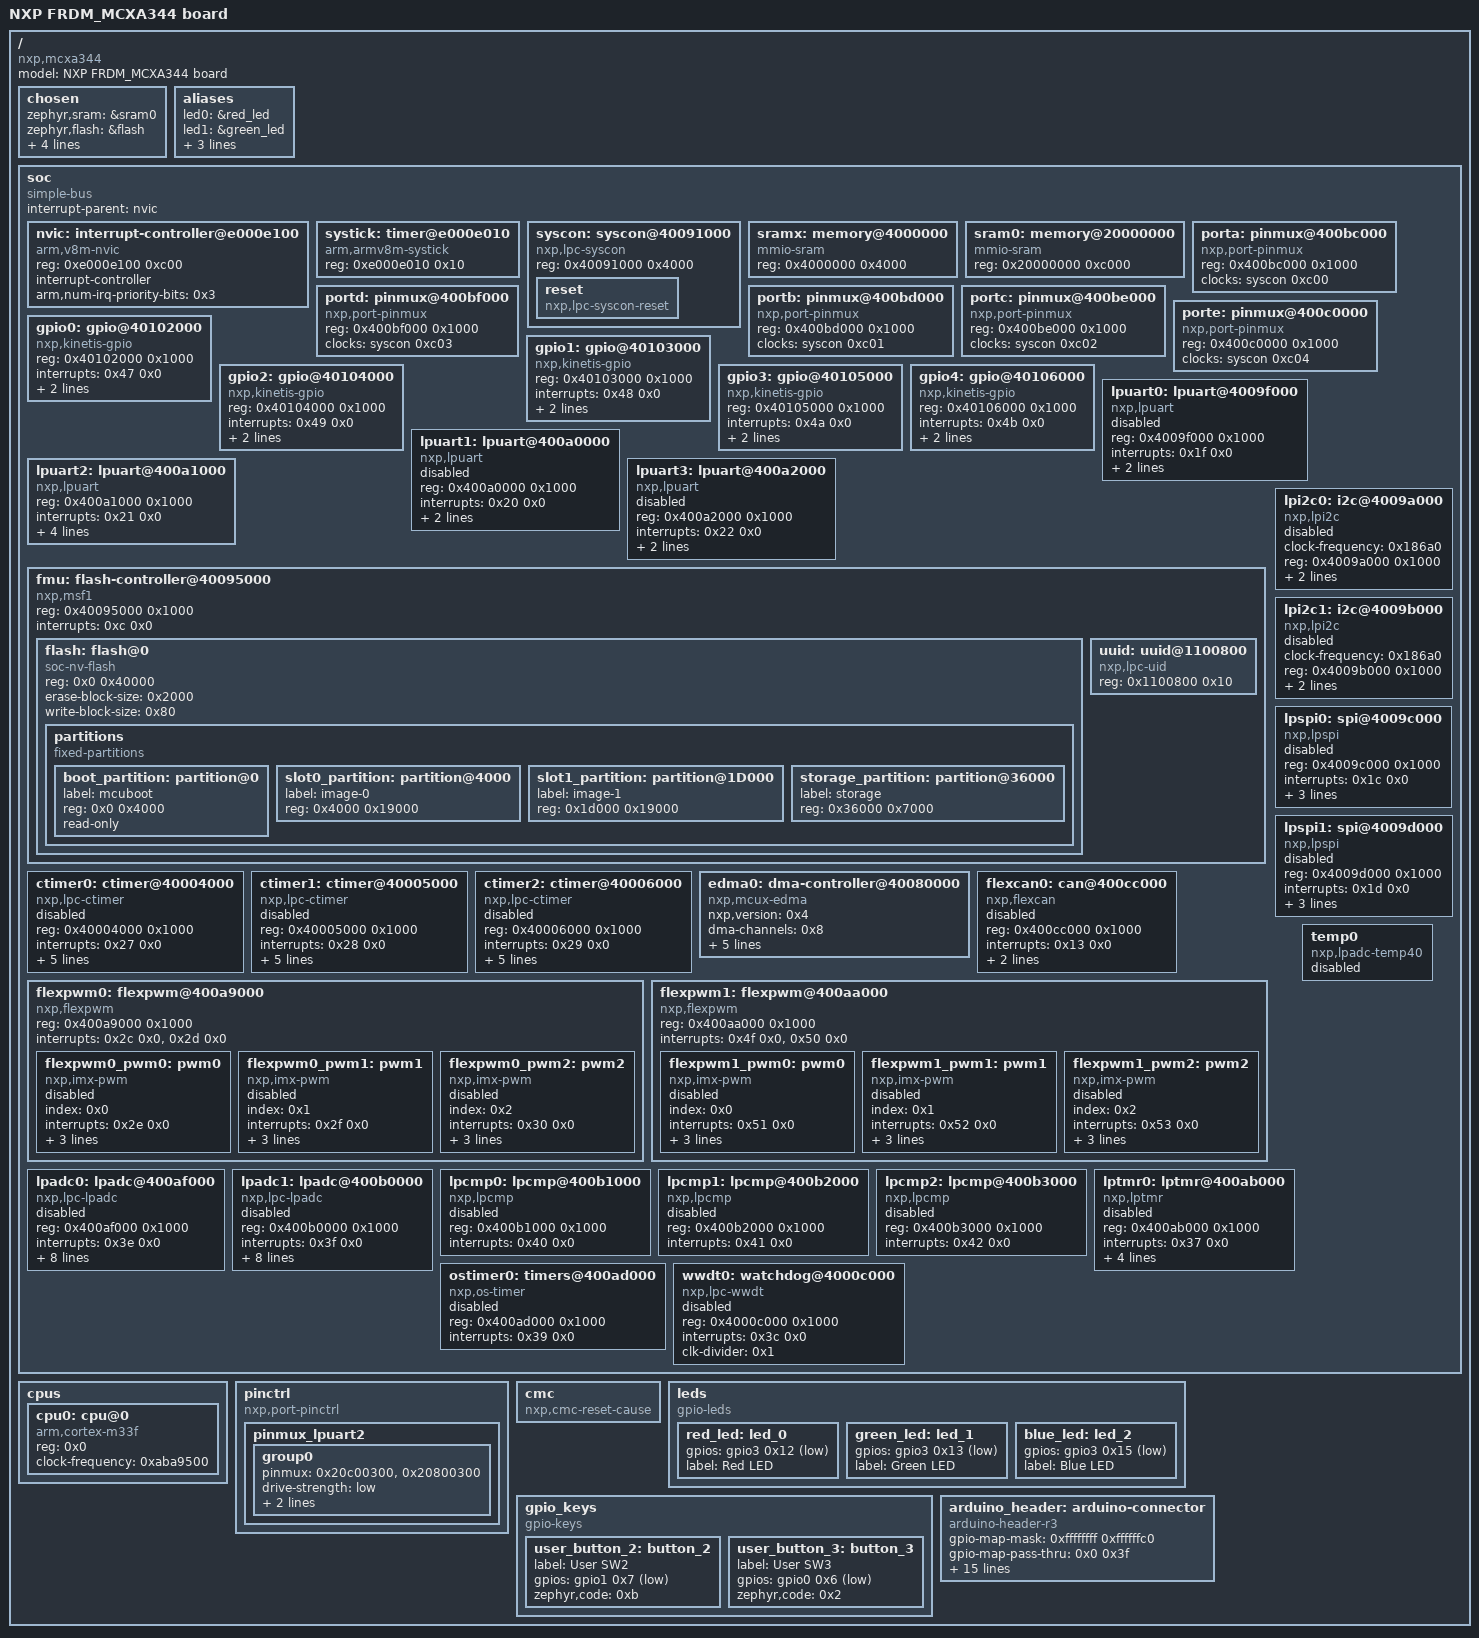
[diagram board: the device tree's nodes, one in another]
/dts-v1/;

/* node '/' defined in zephyr/dts/common/skeleton.dtsi:9 */
/ {
	#address-cells = < 0x1 >;         /* in zephyr/dts/common/skeleton.dtsi:10 */
	#size-cells = < 0x1 >;            /* in zephyr/dts/common/skeleton.dtsi:11 */
	model = "NXP FRDM_MCXA344 board"; /* in zephyr/boards/nxp/frdm_mcxa344/frdm_mcxa344.dts:15 */
	compatible = "nxp,mcxa344",
	             "nxp,mcx";           /* in zephyr/boards/nxp/frdm_mcxa344/frdm_mcxa344.dts:16 */

	/* node '/chosen' defined in zephyr/dts/common/skeleton.dtsi:13 */
	chosen {
		zephyr,sram = &sram0;                     /* in zephyr/boards/nxp/frdm_mcxa344/frdm_mcxa344.dts:27 */
		zephyr,flash = &flash;                    /* in zephyr/boards/nxp/frdm_mcxa344/frdm_mcxa344.dts:28 */
		zephyr,flash-controller = &fmu;           /* in zephyr/boards/nxp/frdm_mcxa344/frdm_mcxa344.dts:29 */
		zephyr,code-partition = &slot0_partition; /* in zephyr/boards/nxp/frdm_mcxa344/frdm_mcxa344.dts:30 */
		zephyr,console = &lpuart2;                /* in zephyr/boards/nxp/frdm_mcxa344/frdm_mcxa344.dts:31 */
		zephyr,shell-uart = &lpuart2;             /* in zephyr/boards/nxp/frdm_mcxa344/frdm_mcxa344.dts:32 */
	};

	/* node '/aliases' defined in zephyr/dts/common/skeleton.dtsi:15 */
	aliases {
		led0 = &red_led;      /* in zephyr/boards/nxp/frdm_mcxa344/frdm_mcxa344.dts:19 */
		led1 = &green_led;    /* in zephyr/boards/nxp/frdm_mcxa344/frdm_mcxa344.dts:20 */
		led2 = &blue_led;     /* in zephyr/boards/nxp/frdm_mcxa344/frdm_mcxa344.dts:21 */
		sw0 = &user_button_2; /* in zephyr/boards/nxp/frdm_mcxa344/frdm_mcxa344.dts:22 */
		sw1 = &user_button_3; /* in zephyr/boards/nxp/frdm_mcxa344/frdm_mcxa344.dts:23 */
	};

	/* node '/soc' defined in zephyr/dts/arm/armv8-m.dtsi:6 */
	soc {
		#address-cells = < 0x1 >;     /* in zephyr/dts/arm/armv8-m.dtsi:7 */
		#size-cells = < 0x1 >;        /* in zephyr/dts/arm/armv8-m.dtsi:8 */
		compatible = "simple-bus";    /* in zephyr/dts/arm/armv8-m.dtsi:9 */
		interrupt-parent = < &nvic >; /* in zephyr/dts/arm/armv8-m.dtsi:10 */
		ranges;                       /* in zephyr/dts/arm/armv8-m.dtsi:11 */

		/* node '/soc/interrupt-controller@e000e100' defined in zephyr/dts/arm/armv8-m.dtsi:13 */
		nvic: interrupt-controller@e000e100 {
			#address-cells = < 0x1 >;            /* in zephyr/dts/arm/armv8-m.dtsi:14 */
			compatible = "arm,v8m-nvic";         /* in zephyr/dts/arm/armv8-m.dtsi:15 */
			reg = < 0xe000e100 0xc00 >;          /* in zephyr/dts/arm/armv8-m.dtsi:16 */
			interrupt-controller;                /* in zephyr/dts/arm/armv8-m.dtsi:17 */
			#interrupt-cells = < 0x2 >;          /* in zephyr/dts/arm/armv8-m.dtsi:18 */
			arm,num-irq-priority-bits = < 0x3 >; /* in zephyr/dts/arm/nxp/nxp_mcxa344.dtsi:476 */
			phandle = < 0x1 >;                   /* in zephyr/dts/arm/armv8-m.dtsi:10 */
		};

		/* node '/soc/timer@e000e010' defined in zephyr/dts/arm/armv8-m.dtsi:21 */
		systick: timer@e000e010 {
			compatible = "arm,armv8m-systick"; /* in zephyr/dts/arm/armv8-m.dtsi:22 */
			reg = < 0xe000e010 0x10 >;         /* in zephyr/dts/arm/armv8-m.dtsi:23 */
		};

		/* node '/soc/syscon@40091000' defined in zephyr/dts/arm/nxp/nxp_mcxa344.dtsi:37 */
		syscon: syscon@40091000 {
			compatible = "nxp,lpc-syscon"; /* in zephyr/dts/arm/nxp/nxp_mcxa344.dtsi:38 */
			reg = < 0x40091000 0x4000 >;   /* in zephyr/dts/arm/nxp/nxp_mcxa344.dtsi:39 */
			#clock-cells = < 0x1 >;        /* in zephyr/dts/arm/nxp/nxp_mcxa344.dtsi:40 */
			phandle = < 0x2 >;             /* in zephyr/dts/arm/nxp/nxp_mcxa344.dtsi:60 */

			/* node '/soc/syscon@40091000/reset' defined in zephyr/dts/arm/nxp/nxp_mcxa344.dtsi:41 */
			reset: reset {
				compatible = "nxp,lpc-syscon-reset"; /* in zephyr/dts/arm/nxp/nxp_mcxa344.dtsi:42 */
				#reset-cells = < 0x1 >;              /* in zephyr/dts/arm/nxp/nxp_mcxa344.dtsi:43 */
			};
		};

		/* node '/soc/memory@4000000' defined in zephyr/dts/arm/nxp/nxp_mcxa344.dtsi:47 */
		sramx: memory@4000000 {
			compatible = "mmio-sram";   /* in zephyr/dts/arm/nxp/nxp_mcxa344.dtsi:48 */
			reg = < 0x4000000 0x4000 >; /* in zephyr/dts/arm/nxp/nxp_mcxa344.dtsi:49 */
		};

		/* node '/soc/memory@20000000' defined in zephyr/dts/arm/nxp/nxp_mcxa344.dtsi:52 */
		sram0: memory@20000000 {
			compatible = "mmio-sram";    /* in zephyr/dts/arm/nxp/nxp_mcxa344.dtsi:53 */
			reg = < 0x20000000 0xc000 >; /* in zephyr/dts/arm/nxp/nxp_mcxa344.dtsi:54 */
		};

		/* node '/soc/pinmux@400bc000' defined in zephyr/dts/arm/nxp/nxp_mcxa344.dtsi:57 */
		porta: pinmux@400bc000 {
			compatible = "nxp,port-pinmux"; /* in zephyr/dts/arm/nxp/nxp_mcxa344.dtsi:58 */
			reg = < 0x400bc000 0x1000 >;    /* in zephyr/dts/arm/nxp/nxp_mcxa344.dtsi:59 */
			clocks = < &syscon 0xc00 >;     /* in zephyr/dts/arm/nxp/nxp_mcxa344.dtsi:60 */
			phandle = < 0x3 >;              /* in zephyr/dts/arm/nxp/nxp_mcxa344.dtsi:94 */
		};

		/* node '/soc/pinmux@400bd000' defined in zephyr/dts/arm/nxp/nxp_mcxa344.dtsi:63 */
		portb: pinmux@400bd000 {
			compatible = "nxp,port-pinmux"; /* in zephyr/dts/arm/nxp/nxp_mcxa344.dtsi:64 */
			reg = < 0x400bd000 0x1000 >;    /* in zephyr/dts/arm/nxp/nxp_mcxa344.dtsi:65 */
			clocks = < &syscon 0xc01 >;     /* in zephyr/dts/arm/nxp/nxp_mcxa344.dtsi:66 */
			phandle = < 0x4 >;              /* in zephyr/dts/arm/nxp/nxp_mcxa344.dtsi:104 */
		};

		/* node '/soc/pinmux@400be000' defined in zephyr/dts/arm/nxp/nxp_mcxa344.dtsi:69 */
		portc: pinmux@400be000 {
			compatible = "nxp,port-pinmux"; /* in zephyr/dts/arm/nxp/nxp_mcxa344.dtsi:70 */
			reg = < 0x400be000 0x1000 >;    /* in zephyr/dts/arm/nxp/nxp_mcxa344.dtsi:71 */
			clocks = < &syscon 0xc02 >;     /* in zephyr/dts/arm/nxp/nxp_mcxa344.dtsi:72 */
			phandle = < 0x5 >;              /* in zephyr/dts/arm/nxp/nxp_mcxa344.dtsi:114 */
		};

		/* node '/soc/pinmux@400bf000' defined in zephyr/dts/arm/nxp/nxp_mcxa344.dtsi:75 */
		portd: pinmux@400bf000 {
			compatible = "nxp,port-pinmux"; /* in zephyr/dts/arm/nxp/nxp_mcxa344.dtsi:76 */
			reg = < 0x400bf000 0x1000 >;    /* in zephyr/dts/arm/nxp/nxp_mcxa344.dtsi:77 */
			clocks = < &syscon 0xc03 >;     /* in zephyr/dts/arm/nxp/nxp_mcxa344.dtsi:78 */
			phandle = < 0x6 >;              /* in zephyr/dts/arm/nxp/nxp_mcxa344.dtsi:124 */
		};

		/* node '/soc/pinmux@400c0000' defined in zephyr/dts/arm/nxp/nxp_mcxa344.dtsi:81 */
		porte: pinmux@400c0000 {
			compatible = "nxp,port-pinmux"; /* in zephyr/dts/arm/nxp/nxp_mcxa344.dtsi:82 */
			reg = < 0x400c0000 0x1000 >;    /* in zephyr/dts/arm/nxp/nxp_mcxa344.dtsi:83 */
			clocks = < &syscon 0xc04 >;     /* in zephyr/dts/arm/nxp/nxp_mcxa344.dtsi:84 */
			phandle = < 0x7 >;              /* in zephyr/dts/arm/nxp/nxp_mcxa344.dtsi:134 */
		};

		/* node '/soc/gpio@40102000' defined in zephyr/dts/arm/nxp/nxp_mcxa344.dtsi:87 */
		gpio0: gpio@40102000 {
			compatible = "nxp,kinetis-gpio"; /* in zephyr/dts/arm/nxp/nxp_mcxa344.dtsi:88 */
			reg = < 0x40102000 0x1000 >;     /* in zephyr/dts/arm/nxp/nxp_mcxa344.dtsi:90 */
			interrupts = < 0x47 0x0 >;       /* in zephyr/dts/arm/nxp/nxp_mcxa344.dtsi:91 */
			gpio-controller;                 /* in zephyr/dts/arm/nxp/nxp_mcxa344.dtsi:92 */
			#gpio-cells = < 0x2 >;           /* in zephyr/dts/arm/nxp/nxp_mcxa344.dtsi:93 */
			nxp,kinetis-port = < &porta >;   /* in zephyr/dts/arm/nxp/nxp_mcxa344.dtsi:94 */
			status = "okay";                 /* in zephyr/boards/nxp/frdm_mcxa344/frdm_mcxa344.dts:109 */
			phandle = < 0xc >;               /* in zephyr/boards/nxp/frdm_mcxa344/frdm_mcxa344.dts:65 */
		};

		/* node '/soc/gpio@40103000' defined in zephyr/dts/arm/nxp/nxp_mcxa344.dtsi:97 */
		gpio1: gpio@40103000 {
			compatible = "nxp,kinetis-gpio"; /* in zephyr/dts/arm/nxp/nxp_mcxa344.dtsi:98 */
			reg = < 0x40103000 0x1000 >;     /* in zephyr/dts/arm/nxp/nxp_mcxa344.dtsi:100 */
			interrupts = < 0x48 0x0 >;       /* in zephyr/dts/arm/nxp/nxp_mcxa344.dtsi:101 */
			gpio-controller;                 /* in zephyr/dts/arm/nxp/nxp_mcxa344.dtsi:102 */
			#gpio-cells = < 0x2 >;           /* in zephyr/dts/arm/nxp/nxp_mcxa344.dtsi:103 */
			nxp,kinetis-port = < &portb >;   /* in zephyr/dts/arm/nxp/nxp_mcxa344.dtsi:104 */
			status = "okay";                 /* in zephyr/boards/nxp/frdm_mcxa344/frdm_mcxa344.dts:113 */
			phandle = < 0xb >;               /* in zephyr/boards/nxp/frdm_mcxa344/frdm_mcxa344.dts:59 */
		};

		/* node '/soc/gpio@40104000' defined in zephyr/dts/arm/nxp/nxp_mcxa344.dtsi:107 */
		gpio2: gpio@40104000 {
			compatible = "nxp,kinetis-gpio"; /* in zephyr/dts/arm/nxp/nxp_mcxa344.dtsi:108 */
			reg = < 0x40104000 0x1000 >;     /* in zephyr/dts/arm/nxp/nxp_mcxa344.dtsi:110 */
			interrupts = < 0x49 0x0 >;       /* in zephyr/dts/arm/nxp/nxp_mcxa344.dtsi:111 */
			gpio-controller;                 /* in zephyr/dts/arm/nxp/nxp_mcxa344.dtsi:112 */
			#gpio-cells = < 0x2 >;           /* in zephyr/dts/arm/nxp/nxp_mcxa344.dtsi:113 */
			nxp,kinetis-port = < &portc >;   /* in zephyr/dts/arm/nxp/nxp_mcxa344.dtsi:114 */
			status = "okay";                 /* in zephyr/boards/nxp/frdm_mcxa344/frdm_mcxa344.dts:117 */
			phandle = < 0xd >;               /* in zephyr/boards/nxp/frdm_mcxa344/frdm_mcxa344.dts:75 */
		};

		/* node '/soc/gpio@40105000' defined in zephyr/dts/arm/nxp/nxp_mcxa344.dtsi:117 */
		gpio3: gpio@40105000 {
			compatible = "nxp,kinetis-gpio"; /* in zephyr/dts/arm/nxp/nxp_mcxa344.dtsi:118 */
			reg = < 0x40105000 0x1000 >;     /* in zephyr/dts/arm/nxp/nxp_mcxa344.dtsi:120 */
			interrupts = < 0x4a 0x0 >;       /* in zephyr/dts/arm/nxp/nxp_mcxa344.dtsi:121 */
			gpio-controller;                 /* in zephyr/dts/arm/nxp/nxp_mcxa344.dtsi:122 */
			#gpio-cells = < 0x2 >;           /* in zephyr/dts/arm/nxp/nxp_mcxa344.dtsi:123 */
			nxp,kinetis-port = < &portd >;   /* in zephyr/dts/arm/nxp/nxp_mcxa344.dtsi:124 */
			status = "okay";                 /* in zephyr/boards/nxp/frdm_mcxa344/frdm_mcxa344.dts:121 */
			phandle = < 0xa >;               /* in zephyr/boards/nxp/frdm_mcxa344/frdm_mcxa344.dts:39 */
		};

		/* node '/soc/gpio@40106000' defined in zephyr/dts/arm/nxp/nxp_mcxa344.dtsi:127 */
		gpio4: gpio@40106000 {
			compatible = "nxp,kinetis-gpio"; /* in zephyr/dts/arm/nxp/nxp_mcxa344.dtsi:128 */
			reg = < 0x40106000 0x1000 >;     /* in zephyr/dts/arm/nxp/nxp_mcxa344.dtsi:130 */
			interrupts = < 0x4b 0x0 >;       /* in zephyr/dts/arm/nxp/nxp_mcxa344.dtsi:131 */
			gpio-controller;                 /* in zephyr/dts/arm/nxp/nxp_mcxa344.dtsi:132 */
			#gpio-cells = < 0x2 >;           /* in zephyr/dts/arm/nxp/nxp_mcxa344.dtsi:133 */
			nxp,kinetis-port = < &porte >;   /* in zephyr/dts/arm/nxp/nxp_mcxa344.dtsi:134 */
			status = "okay";                 /* in zephyr/boards/nxp/frdm_mcxa344/frdm_mcxa344.dts:125 */
			phandle = < 0xe >;               /* in zephyr/boards/nxp/frdm_mcxa344/frdm_mcxa344.dts:75 */
		};

		/* node '/soc/lpuart@4009f000' defined in zephyr/dts/arm/nxp/nxp_mcxa344.dtsi:137 */
		lpuart0: lpuart@4009f000 {
			compatible = "nxp,lpuart";   /* in zephyr/dts/arm/nxp/nxp_mcxa344.dtsi:138 */
			status = "disabled";         /* in zephyr/dts/arm/nxp/nxp_mcxa344.dtsi:139 */
			reg = < 0x4009f000 0x1000 >; /* in zephyr/dts/arm/nxp/nxp_mcxa344.dtsi:140 */
			interrupts = < 0x1f 0x0 >;   /* in zephyr/dts/arm/nxp/nxp_mcxa344.dtsi:141 */
			clocks = < &syscon 0x1300 >; /* in zephyr/dts/arm/nxp/nxp_mcxa344.dtsi:142 */
			dmas = < &edma0 0x0 0x15 >,
			       < &edma0 0x1 0x16 >;  /* in zephyr/dts/arm/nxp/nxp_mcxa344.dtsi:144 */
			dma-names = "rx",
			            "tx";            /* in zephyr/dts/arm/nxp/nxp_mcxa344.dtsi:145 */
		};

		/* node '/soc/lpuart@400a0000' defined in zephyr/dts/arm/nxp/nxp_mcxa344.dtsi:148 */
		lpuart1: lpuart@400a0000 {
			compatible = "nxp,lpuart";   /* in zephyr/dts/arm/nxp/nxp_mcxa344.dtsi:149 */
			status = "disabled";         /* in zephyr/dts/arm/nxp/nxp_mcxa344.dtsi:150 */
			reg = < 0x400a0000 0x1000 >; /* in zephyr/dts/arm/nxp/nxp_mcxa344.dtsi:151 */
			interrupts = < 0x20 0x0 >;   /* in zephyr/dts/arm/nxp/nxp_mcxa344.dtsi:152 */
			clocks = < &syscon 0x1301 >; /* in zephyr/dts/arm/nxp/nxp_mcxa344.dtsi:153 */
			dmas = < &edma0 0x2 0x17 >,
			       < &edma0 0x3 0x18 >;  /* in zephyr/dts/arm/nxp/nxp_mcxa344.dtsi:155 */
			dma-names = "rx",
			            "tx";            /* in zephyr/dts/arm/nxp/nxp_mcxa344.dtsi:156 */
		};

		/* node '/soc/lpuart@400a1000' defined in zephyr/dts/arm/nxp/nxp_mcxa344.dtsi:159 */
		lpuart2: lpuart@400a1000 {
			compatible = "nxp,lpuart";       /* in zephyr/dts/arm/nxp/nxp_mcxa344.dtsi:160 */
			reg = < 0x400a1000 0x1000 >;     /* in zephyr/dts/arm/nxp/nxp_mcxa344.dtsi:162 */
			interrupts = < 0x21 0x0 >;       /* in zephyr/dts/arm/nxp/nxp_mcxa344.dtsi:163 */
			clocks = < &syscon 0x1302 >;     /* in zephyr/dts/arm/nxp/nxp_mcxa344.dtsi:164 */
			dmas = < &edma0 0x4 0x19 >,
			       < &edma0 0x5 0x1a >;      /* in zephyr/dts/arm/nxp/nxp_mcxa344.dtsi:166 */
			dma-names = "rx",
			            "tx";                /* in zephyr/dts/arm/nxp/nxp_mcxa344.dtsi:167 */
			status = "okay";                 /* in zephyr/boards/nxp/frdm_mcxa344/frdm_mcxa344.dts:129 */
			current-speed = < 0x1c200 >;     /* in zephyr/boards/nxp/frdm_mcxa344/frdm_mcxa344.dts:130 */
			pinctrl-0 = < &pinmux_lpuart2 >; /* in zephyr/boards/nxp/frdm_mcxa344/frdm_mcxa344.dts:131 */
			pinctrl-names = "default";       /* in zephyr/boards/nxp/frdm_mcxa344/frdm_mcxa344.dts:132 */
		};

		/* node '/soc/lpuart@400a2000' defined in zephyr/dts/arm/nxp/nxp_mcxa344.dtsi:170 */
		lpuart3: lpuart@400a2000 {
			compatible = "nxp,lpuart";   /* in zephyr/dts/arm/nxp/nxp_mcxa344.dtsi:171 */
			status = "disabled";         /* in zephyr/dts/arm/nxp/nxp_mcxa344.dtsi:172 */
			reg = < 0x400a2000 0x1000 >; /* in zephyr/dts/arm/nxp/nxp_mcxa344.dtsi:173 */
			interrupts = < 0x22 0x0 >;   /* in zephyr/dts/arm/nxp/nxp_mcxa344.dtsi:174 */
			clocks = < &syscon 0x1303 >; /* in zephyr/dts/arm/nxp/nxp_mcxa344.dtsi:175 */
			dmas = < &edma0 0x6 0x1b >,
			       < &edma0 0x7 0x1c >;  /* in zephyr/dts/arm/nxp/nxp_mcxa344.dtsi:177 */
			dma-names = "rx",
			            "tx";            /* in zephyr/dts/arm/nxp/nxp_mcxa344.dtsi:178 */
		};

		/* node '/soc/flash-controller@40095000' defined in zephyr/dts/arm/nxp/nxp_mcxa344.dtsi:181 */
		fmu: flash-controller@40095000 {
			compatible = "nxp,msf1";     /* in zephyr/dts/arm/nxp/nxp_mcxa344.dtsi:182 */
			reg = < 0x40095000 0x1000 >; /* in zephyr/dts/arm/nxp/nxp_mcxa344.dtsi:183 */
			interrupts = < 0xc 0x0 >;    /* in zephyr/dts/arm/nxp/nxp_mcxa344.dtsi:184 */
			#address-cells = < 0x1 >;    /* in zephyr/dts/arm/nxp/nxp_mcxa344.dtsi:186 */
			#size-cells = < 0x1 >;       /* in zephyr/dts/arm/nxp/nxp_mcxa344.dtsi:187 */

			/* node '/soc/flash-controller@40095000/flash@0' defined in zephyr/dts/arm/nxp/nxp_mcxa344.dtsi:189 */
			flash: flash@0 {
				compatible = "soc-nv-flash";   /* in zephyr/dts/arm/nxp/nxp_mcxa344.dtsi:190 */
				reg = < 0x0 0x40000 >;         /* in zephyr/dts/arm/nxp/nxp_mcxa344.dtsi:191 */
				erase-block-size = < 0x2000 >; /* in zephyr/dts/arm/nxp/nxp_mcxa344.dtsi:192 */
				write-block-size = < 0x80 >;   /* in zephyr/dts/arm/nxp/nxp_mcxa344.dtsi:193 */

				/* node '/soc/flash-controller@40095000/flash@0/partitions' defined in zephyr/boards/nxp/frdm_mcxa344/frdm_mcxa344.dts:136 */
				partitions {
					compatible = "fixed-partitions"; /* in zephyr/boards/nxp/frdm_mcxa344/frdm_mcxa344.dts:137 */
					#address-cells = < 0x1 >;        /* in zephyr/boards/nxp/frdm_mcxa344/frdm_mcxa344.dts:138 */
					#size-cells = < 0x1 >;           /* in zephyr/boards/nxp/frdm_mcxa344/frdm_mcxa344.dts:139 */

					/* node '/soc/flash-controller@40095000/flash@0/partitions/partition@0' defined in zephyr/boards/nxp/frdm_mcxa344/frdm_mcxa344.dts:141 */
					boot_partition: partition@0 {
						label = "mcuboot";    /* in zephyr/boards/nxp/frdm_mcxa344/frdm_mcxa344.dts:142 */
						reg = < 0x0 0x4000 >; /* in zephyr/boards/nxp/frdm_mcxa344/frdm_mcxa344.dts:143 */
						read-only;            /* in zephyr/boards/nxp/frdm_mcxa344/frdm_mcxa344.dts:144 */
					};

					/* node '/soc/flash-controller@40095000/flash@0/partitions/partition@4000' defined in zephyr/boards/nxp/frdm_mcxa344/frdm_mcxa344.dts:147 */
					slot0_partition: partition@4000 {
						label = "image-0";        /* in zephyr/boards/nxp/frdm_mcxa344/frdm_mcxa344.dts:148 */
						reg = < 0x4000 0x19000 >; /* in zephyr/boards/nxp/frdm_mcxa344/frdm_mcxa344.dts:149 */
					};

					/* node '/soc/flash-controller@40095000/flash@0/partitions/partition@1D000' defined in zephyr/boards/nxp/frdm_mcxa344/frdm_mcxa344.dts:152 */
					slot1_partition: partition@1D000 {
						label = "image-1";         /* in zephyr/boards/nxp/frdm_mcxa344/frdm_mcxa344.dts:153 */
						reg = < 0x1d000 0x19000 >; /* in zephyr/boards/nxp/frdm_mcxa344/frdm_mcxa344.dts:154 */
					};

					/* node '/soc/flash-controller@40095000/flash@0/partitions/partition@36000' defined in zephyr/boards/nxp/frdm_mcxa344/frdm_mcxa344.dts:157 */
					storage_partition: partition@36000 {
						label = "storage";        /* in zephyr/boards/nxp/frdm_mcxa344/frdm_mcxa344.dts:158 */
						reg = < 0x36000 0x7000 >; /* in zephyr/boards/nxp/frdm_mcxa344/frdm_mcxa344.dts:159 */
					};
				};
			};

			/* node '/soc/flash-controller@40095000/uuid@1100800' defined in zephyr/dts/arm/nxp/nxp_mcxa344.dtsi:196 */
			uuid: uuid@1100800 {
				compatible = "nxp,lpc-uid"; /* in zephyr/dts/arm/nxp/nxp_mcxa344.dtsi:197 */
				reg = < 0x1100800 0x10 >;   /* in zephyr/dts/arm/nxp/nxp_mcxa344.dtsi:198 */
			};
		};

		/* node '/soc/ctimer@40004000' defined in zephyr/dts/arm/nxp/nxp_mcxa344.dtsi:202 */
		ctimer0: ctimer@40004000 {
			compatible = "nxp,lpc-ctimer"; /* in zephyr/dts/arm/nxp/nxp_mcxa344.dtsi:203 */
			reg = < 0x40004000 0x1000 >;   /* in zephyr/dts/arm/nxp/nxp_mcxa344.dtsi:204 */
			interrupts = < 0x27 0x0 >;     /* in zephyr/dts/arm/nxp/nxp_mcxa344.dtsi:205 */
			status = "disabled";           /* in zephyr/dts/arm/nxp/nxp_mcxa344.dtsi:206 */
			clk-source = < 0x1 >;          /* in zephyr/dts/arm/nxp/nxp_mcxa344.dtsi:207 */
			clocks = < &syscon 0x0 >;      /* in zephyr/dts/arm/nxp/nxp_mcxa344.dtsi:208 */
			mode = < 0x0 >;                /* in zephyr/dts/arm/nxp/nxp_mcxa344.dtsi:209 */
			input = < 0x0 >;               /* in zephyr/dts/arm/nxp/nxp_mcxa344.dtsi:210 */
			prescale = < 0x0 >;            /* in zephyr/dts/arm/nxp/nxp_mcxa344.dtsi:211 */
		};

		/* node '/soc/ctimer@40005000' defined in zephyr/dts/arm/nxp/nxp_mcxa344.dtsi:214 */
		ctimer1: ctimer@40005000 {
			compatible = "nxp,lpc-ctimer"; /* in zephyr/dts/arm/nxp/nxp_mcxa344.dtsi:215 */
			reg = < 0x40005000 0x1000 >;   /* in zephyr/dts/arm/nxp/nxp_mcxa344.dtsi:216 */
			interrupts = < 0x28 0x0 >;     /* in zephyr/dts/arm/nxp/nxp_mcxa344.dtsi:217 */
			status = "disabled";           /* in zephyr/dts/arm/nxp/nxp_mcxa344.dtsi:218 */
			clk-source = < 0x1 >;          /* in zephyr/dts/arm/nxp/nxp_mcxa344.dtsi:219 */
			clocks = < &syscon 0x1 >;      /* in zephyr/dts/arm/nxp/nxp_mcxa344.dtsi:220 */
			mode = < 0x0 >;                /* in zephyr/dts/arm/nxp/nxp_mcxa344.dtsi:221 */
			input = < 0x0 >;               /* in zephyr/dts/arm/nxp/nxp_mcxa344.dtsi:222 */
			prescale = < 0x0 >;            /* in zephyr/dts/arm/nxp/nxp_mcxa344.dtsi:223 */
		};

		/* node '/soc/ctimer@40006000' defined in zephyr/dts/arm/nxp/nxp_mcxa344.dtsi:226 */
		ctimer2: ctimer@40006000 {
			compatible = "nxp,lpc-ctimer"; /* in zephyr/dts/arm/nxp/nxp_mcxa344.dtsi:227 */
			reg = < 0x40006000 0x1000 >;   /* in zephyr/dts/arm/nxp/nxp_mcxa344.dtsi:228 */
			interrupts = < 0x29 0x0 >;     /* in zephyr/dts/arm/nxp/nxp_mcxa344.dtsi:229 */
			status = "disabled";           /* in zephyr/dts/arm/nxp/nxp_mcxa344.dtsi:230 */
			clk-source = < 0x1 >;          /* in zephyr/dts/arm/nxp/nxp_mcxa344.dtsi:231 */
			clocks = < &syscon 0x2 >;      /* in zephyr/dts/arm/nxp/nxp_mcxa344.dtsi:232 */
			mode = < 0x0 >;                /* in zephyr/dts/arm/nxp/nxp_mcxa344.dtsi:233 */
			input = < 0x0 >;               /* in zephyr/dts/arm/nxp/nxp_mcxa344.dtsi:234 */
			prescale = < 0x0 >;            /* in zephyr/dts/arm/nxp/nxp_mcxa344.dtsi:235 */
		};

		/* node '/soc/dma-controller@40080000' defined in zephyr/dts/arm/nxp/nxp_mcxa344.dtsi:238 */
		edma0: dma-controller@40080000 {
			#dma-cells = < 0x2 >;         /* in zephyr/dts/arm/nxp/nxp_mcxa344.dtsi:239 */
			compatible = "nxp,mcux-edma"; /* in zephyr/dts/arm/nxp/nxp_mcxa344.dtsi:240 */
			nxp,version = < 0x4 >;        /* in zephyr/dts/arm/nxp/nxp_mcxa344.dtsi:241 */
			dma-channels = < 0x8 >;       /* in zephyr/dts/arm/nxp/nxp_mcxa344.dtsi:242 */
			dma-requests = < 0x56 >;      /* in zephyr/dts/arm/nxp/nxp_mcxa344.dtsi:243 */
			reg = < 0x40080000 0x1000 >;  /* in zephyr/dts/arm/nxp/nxp_mcxa344.dtsi:245 */
			interrupts = < 0x2 0x0 >,
			             < 0x3 0x0 >,
			             < 0x4 0x0 >,
			             < 0x5 0x0 >,
			             < 0x6 0x0 >,
			             < 0x7 0x0 >,
			             < 0x8 0x0 >,
			             < 0x9 0x0 >;     /* in zephyr/dts/arm/nxp/nxp_mcxa344.dtsi:246 */
			no-error-irq;                 /* in zephyr/dts/arm/nxp/nxp_mcxa344.dtsi:248 */
			status = "okay";              /* in zephyr/boards/nxp/frdm_mcxa344/frdm_mcxa344.dts:105 */
			phandle = < 0x8 >;            /* in zephyr/dts/arm/nxp/nxp_mcxa344.dtsi:144 */
		};

		/* node '/soc/can@400cc000' defined in zephyr/dts/arm/nxp/nxp_mcxa344.dtsi:252 */
		flexcan0: can@400cc000 {
			compatible = "nxp,flexcan";  /* in zephyr/dts/arm/nxp/nxp_mcxa344.dtsi:253 */
			reg = < 0x400cc000 0x1000 >; /* in zephyr/dts/arm/nxp/nxp_mcxa344.dtsi:254 */
			interrupts = < 0x13 0x0 >;   /* in zephyr/dts/arm/nxp/nxp_mcxa344.dtsi:255 */
			interrupt-names = "common";  /* in zephyr/dts/arm/nxp/nxp_mcxa344.dtsi:256 */
			clocks = < &syscon 0x1000 >; /* in zephyr/dts/arm/nxp/nxp_mcxa344.dtsi:257 */
			clk-source = < 0x0 >;        /* in zephyr/dts/arm/nxp/nxp_mcxa344.dtsi:258 */
			status = "disabled";         /* in zephyr/dts/arm/nxp/nxp_mcxa344.dtsi:259 */
		};

		/* node '/soc/flexpwm@400a9000' defined in zephyr/dts/arm/nxp/nxp_mcxa344.dtsi:262 */
		flexpwm0: flexpwm@400a9000 {
			compatible = "nxp,flexpwm";       /* in zephyr/dts/arm/nxp/nxp_mcxa344.dtsi:263 */
			reg = < 0x400a9000 0x1000 >;      /* in zephyr/dts/arm/nxp/nxp_mcxa344.dtsi:264 */
			interrupt-names = "RELOAD-ERROR",
			                  "FAULT";        /* in zephyr/dts/arm/nxp/nxp_mcxa344.dtsi:265 */
			interrupts = < 0x2c 0x0 >,
			             < 0x2d 0x0 >;        /* in zephyr/dts/arm/nxp/nxp_mcxa344.dtsi:266 */

			/* node '/soc/flexpwm@400a9000/pwm0' defined in zephyr/dts/arm/nxp/nxp_mcxa344.dtsi:267 */
			flexpwm0_pwm0: pwm0 {
				compatible = "nxp,imx-pwm"; /* in zephyr/dts/arm/nxp/nxp_mcxa344.dtsi:268 */
				index = < 0x0 >;            /* in zephyr/dts/arm/nxp/nxp_mcxa344.dtsi:269 */
				interrupts = < 0x2e 0x0 >;  /* in zephyr/dts/arm/nxp/nxp_mcxa344.dtsi:270 */
				#pwm-cells = < 0x3 >;       /* in zephyr/dts/arm/nxp/nxp_mcxa344.dtsi:271 */
				clocks = < &syscon 0x400 >; /* in zephyr/dts/arm/nxp/nxp_mcxa344.dtsi:272 */
				nxp,prescaler = < 0x80 >;   /* in zephyr/dts/arm/nxp/nxp_mcxa344.dtsi:273 */
				status = "disabled";        /* in zephyr/dts/arm/nxp/nxp_mcxa344.dtsi:274 */
				run-in-wait;                /* in zephyr/dts/arm/nxp/nxp_mcxa344.dtsi:275 */
			};

			/* node '/soc/flexpwm@400a9000/pwm1' defined in zephyr/dts/arm/nxp/nxp_mcxa344.dtsi:278 */
			flexpwm0_pwm1: pwm1 {
				compatible = "nxp,imx-pwm"; /* in zephyr/dts/arm/nxp/nxp_mcxa344.dtsi:279 */
				index = < 0x1 >;            /* in zephyr/dts/arm/nxp/nxp_mcxa344.dtsi:280 */
				interrupts = < 0x2f 0x0 >;  /* in zephyr/dts/arm/nxp/nxp_mcxa344.dtsi:281 */
				#pwm-cells = < 0x3 >;       /* in zephyr/dts/arm/nxp/nxp_mcxa344.dtsi:282 */
				clocks = < &syscon 0x400 >; /* in zephyr/dts/arm/nxp/nxp_mcxa344.dtsi:283 */
				nxp,prescaler = < 0x80 >;   /* in zephyr/dts/arm/nxp/nxp_mcxa344.dtsi:284 */
				status = "disabled";        /* in zephyr/dts/arm/nxp/nxp_mcxa344.dtsi:285 */
				run-in-wait;                /* in zephyr/dts/arm/nxp/nxp_mcxa344.dtsi:286 */
			};

			/* node '/soc/flexpwm@400a9000/pwm2' defined in zephyr/dts/arm/nxp/nxp_mcxa344.dtsi:289 */
			flexpwm0_pwm2: pwm2 {
				compatible = "nxp,imx-pwm"; /* in zephyr/dts/arm/nxp/nxp_mcxa344.dtsi:290 */
				index = < 0x2 >;            /* in zephyr/dts/arm/nxp/nxp_mcxa344.dtsi:291 */
				interrupts = < 0x30 0x0 >;  /* in zephyr/dts/arm/nxp/nxp_mcxa344.dtsi:292 */
				#pwm-cells = < 0x3 >;       /* in zephyr/dts/arm/nxp/nxp_mcxa344.dtsi:293 */
				clocks = < &syscon 0x400 >; /* in zephyr/dts/arm/nxp/nxp_mcxa344.dtsi:294 */
				nxp,prescaler = < 0x80 >;   /* in zephyr/dts/arm/nxp/nxp_mcxa344.dtsi:295 */
				status = "disabled";        /* in zephyr/dts/arm/nxp/nxp_mcxa344.dtsi:296 */
				run-in-wait;                /* in zephyr/dts/arm/nxp/nxp_mcxa344.dtsi:297 */
			};
		};

		/* node '/soc/flexpwm@400aa000' defined in zephyr/dts/arm/nxp/nxp_mcxa344.dtsi:301 */
		flexpwm1: flexpwm@400aa000 {
			compatible = "nxp,flexpwm";       /* in zephyr/dts/arm/nxp/nxp_mcxa344.dtsi:302 */
			reg = < 0x400aa000 0x1000 >;      /* in zephyr/dts/arm/nxp/nxp_mcxa344.dtsi:303 */
			interrupt-names = "RELOAD-ERROR",
			                  "FAULT";        /* in zephyr/dts/arm/nxp/nxp_mcxa344.dtsi:304 */
			interrupts = < 0x4f 0x0 >,
			             < 0x50 0x0 >;        /* in zephyr/dts/arm/nxp/nxp_mcxa344.dtsi:305 */

			/* node '/soc/flexpwm@400aa000/pwm0' defined in zephyr/dts/arm/nxp/nxp_mcxa344.dtsi:306 */
			flexpwm1_pwm0: pwm0 {
				compatible = "nxp,imx-pwm"; /* in zephyr/dts/arm/nxp/nxp_mcxa344.dtsi:307 */
				index = < 0x0 >;            /* in zephyr/dts/arm/nxp/nxp_mcxa344.dtsi:308 */
				interrupts = < 0x51 0x0 >;  /* in zephyr/dts/arm/nxp/nxp_mcxa344.dtsi:309 */
				#pwm-cells = < 0x3 >;       /* in zephyr/dts/arm/nxp/nxp_mcxa344.dtsi:310 */
				clocks = < &syscon 0x400 >; /* in zephyr/dts/arm/nxp/nxp_mcxa344.dtsi:311 */
				nxp,prescaler = < 0x80 >;   /* in zephyr/dts/arm/nxp/nxp_mcxa344.dtsi:312 */
				status = "disabled";        /* in zephyr/dts/arm/nxp/nxp_mcxa344.dtsi:313 */
				run-in-wait;                /* in zephyr/dts/arm/nxp/nxp_mcxa344.dtsi:314 */
			};

			/* node '/soc/flexpwm@400aa000/pwm1' defined in zephyr/dts/arm/nxp/nxp_mcxa344.dtsi:317 */
			flexpwm1_pwm1: pwm1 {
				compatible = "nxp,imx-pwm"; /* in zephyr/dts/arm/nxp/nxp_mcxa344.dtsi:318 */
				index = < 0x1 >;            /* in zephyr/dts/arm/nxp/nxp_mcxa344.dtsi:319 */
				interrupts = < 0x52 0x0 >;  /* in zephyr/dts/arm/nxp/nxp_mcxa344.dtsi:320 */
				#pwm-cells = < 0x3 >;       /* in zephyr/dts/arm/nxp/nxp_mcxa344.dtsi:321 */
				clocks = < &syscon 0x400 >; /* in zephyr/dts/arm/nxp/nxp_mcxa344.dtsi:322 */
				nxp,prescaler = < 0x80 >;   /* in zephyr/dts/arm/nxp/nxp_mcxa344.dtsi:323 */
				status = "disabled";        /* in zephyr/dts/arm/nxp/nxp_mcxa344.dtsi:324 */
				run-in-wait;                /* in zephyr/dts/arm/nxp/nxp_mcxa344.dtsi:325 */
			};

			/* node '/soc/flexpwm@400aa000/pwm2' defined in zephyr/dts/arm/nxp/nxp_mcxa344.dtsi:328 */
			flexpwm1_pwm2: pwm2 {
				compatible = "nxp,imx-pwm"; /* in zephyr/dts/arm/nxp/nxp_mcxa344.dtsi:329 */
				index = < 0x2 >;            /* in zephyr/dts/arm/nxp/nxp_mcxa344.dtsi:330 */
				interrupts = < 0x53 0x0 >;  /* in zephyr/dts/arm/nxp/nxp_mcxa344.dtsi:331 */
				#pwm-cells = < 0x3 >;       /* in zephyr/dts/arm/nxp/nxp_mcxa344.dtsi:332 */
				clocks = < &syscon 0x400 >; /* in zephyr/dts/arm/nxp/nxp_mcxa344.dtsi:333 */
				nxp,prescaler = < 0x80 >;   /* in zephyr/dts/arm/nxp/nxp_mcxa344.dtsi:334 */
				status = "disabled";        /* in zephyr/dts/arm/nxp/nxp_mcxa344.dtsi:335 */
				run-in-wait;                /* in zephyr/dts/arm/nxp/nxp_mcxa344.dtsi:336 */
			};
		};

		/* node '/soc/lpadc@400af000' defined in zephyr/dts/arm/nxp/nxp_mcxa344.dtsi:340 */
		lpadc0: lpadc@400af000 {
			compatible = "nxp,lpc-lpadc";   /* in zephyr/dts/arm/nxp/nxp_mcxa344.dtsi:341 */
			reg = < 0x400af000 0x1000 >;    /* in zephyr/dts/arm/nxp/nxp_mcxa344.dtsi:342 */
			interrupts = < 0x3e 0x0 >;      /* in zephyr/dts/arm/nxp/nxp_mcxa344.dtsi:343 */
			status = "disabled";            /* in zephyr/dts/arm/nxp/nxp_mcxa344.dtsi:344 */
			clk-divider = < 0x1 >;          /* in zephyr/dts/arm/nxp/nxp_mcxa344.dtsi:345 */
			clk-source = < 0x0 >;           /* in zephyr/dts/arm/nxp/nxp_mcxa344.dtsi:346 */
			voltage-ref = < 0x2 >;          /* in zephyr/dts/arm/nxp/nxp_mcxa344.dtsi:347 */
			calibration-average = < 0x80 >; /* in zephyr/dts/arm/nxp/nxp_mcxa344.dtsi:348 */
			power-level = < 0x0 >;          /* in zephyr/dts/arm/nxp/nxp_mcxa344.dtsi:349 */
			offset-value-a = < 0x0 >;       /* in zephyr/dts/arm/nxp/nxp_mcxa344.dtsi:350 */
			offset-value-b = < 0x0 >;       /* in zephyr/dts/arm/nxp/nxp_mcxa344.dtsi:351 */
			#io-channel-cells = < 0x1 >;    /* in zephyr/dts/arm/nxp/nxp_mcxa344.dtsi:352 */
			clocks = < &syscon 0xf00 >;     /* in zephyr/dts/arm/nxp/nxp_mcxa344.dtsi:353 */
		};

		/* node '/soc/lpadc@400b0000' defined in zephyr/dts/arm/nxp/nxp_mcxa344.dtsi:356 */
		lpadc1: lpadc@400b0000 {
			compatible = "nxp,lpc-lpadc";   /* in zephyr/dts/arm/nxp/nxp_mcxa344.dtsi:357 */
			reg = < 0x400b0000 0x1000 >;    /* in zephyr/dts/arm/nxp/nxp_mcxa344.dtsi:358 */
			interrupts = < 0x3f 0x0 >;      /* in zephyr/dts/arm/nxp/nxp_mcxa344.dtsi:359 */
			status = "disabled";            /* in zephyr/dts/arm/nxp/nxp_mcxa344.dtsi:360 */
			clk-divider = < 0x1 >;          /* in zephyr/dts/arm/nxp/nxp_mcxa344.dtsi:361 */
			clk-source = < 0x0 >;           /* in zephyr/dts/arm/nxp/nxp_mcxa344.dtsi:362 */
			voltage-ref = < 0x2 >;          /* in zephyr/dts/arm/nxp/nxp_mcxa344.dtsi:363 */
			calibration-average = < 0x80 >; /* in zephyr/dts/arm/nxp/nxp_mcxa344.dtsi:364 */
			power-level = < 0x1 >;          /* in zephyr/dts/arm/nxp/nxp_mcxa344.dtsi:365 */
			offset-value-a = < 0x0 >;       /* in zephyr/dts/arm/nxp/nxp_mcxa344.dtsi:366 */
			offset-value-b = < 0x0 >;       /* in zephyr/dts/arm/nxp/nxp_mcxa344.dtsi:367 */
			#io-channel-cells = < 0x1 >;    /* in zephyr/dts/arm/nxp/nxp_mcxa344.dtsi:368 */
			clocks = < &syscon 0xf01 >;     /* in zephyr/dts/arm/nxp/nxp_mcxa344.dtsi:369 */
		};

		/* node '/soc/lpcmp@400b1000' defined in zephyr/dts/arm/nxp/nxp_mcxa344.dtsi:372 */
		lpcmp0: lpcmp@400b1000 {
			compatible = "nxp,lpcmp";    /* in zephyr/dts/arm/nxp/nxp_mcxa344.dtsi:373 */
			reg = < 0x400b1000 0x1000 >; /* in zephyr/dts/arm/nxp/nxp_mcxa344.dtsi:374 */
			interrupts = < 0x40 0x0 >;   /* in zephyr/dts/arm/nxp/nxp_mcxa344.dtsi:375 */
			status = "disabled";         /* in zephyr/dts/arm/nxp/nxp_mcxa344.dtsi:376 */
			#io-channel-cells = < 0x2 >; /* in zephyr/dts/arm/nxp/nxp_mcxa344.dtsi:377 */
		};

		/* node '/soc/lpcmp@400b2000' defined in zephyr/dts/arm/nxp/nxp_mcxa344.dtsi:380 */
		lpcmp1: lpcmp@400b2000 {
			compatible = "nxp,lpcmp";    /* in zephyr/dts/arm/nxp/nxp_mcxa344.dtsi:381 */
			reg = < 0x400b2000 0x1000 >; /* in zephyr/dts/arm/nxp/nxp_mcxa344.dtsi:382 */
			interrupts = < 0x41 0x0 >;   /* in zephyr/dts/arm/nxp/nxp_mcxa344.dtsi:383 */
			status = "disabled";         /* in zephyr/dts/arm/nxp/nxp_mcxa344.dtsi:384 */
			#io-channel-cells = < 0x2 >; /* in zephyr/dts/arm/nxp/nxp_mcxa344.dtsi:385 */
		};

		/* node '/soc/lpcmp@400b3000' defined in zephyr/dts/arm/nxp/nxp_mcxa344.dtsi:388 */
		lpcmp2: lpcmp@400b3000 {
			compatible = "nxp,lpcmp";    /* in zephyr/dts/arm/nxp/nxp_mcxa344.dtsi:389 */
			reg = < 0x400b3000 0x1000 >; /* in zephyr/dts/arm/nxp/nxp_mcxa344.dtsi:390 */
			interrupts = < 0x42 0x0 >;   /* in zephyr/dts/arm/nxp/nxp_mcxa344.dtsi:391 */
			status = "disabled";         /* in zephyr/dts/arm/nxp/nxp_mcxa344.dtsi:392 */
			#io-channel-cells = < 0x2 >; /* in zephyr/dts/arm/nxp/nxp_mcxa344.dtsi:393 */
		};

		/* node '/soc/i2c@4009a000' defined in zephyr/dts/arm/nxp/nxp_mcxa344.dtsi:396 */
		lpi2c0: i2c@4009a000 {
			compatible = "nxp,lpi2c";      /* in zephyr/dts/arm/nxp/nxp_mcxa344.dtsi:397 */
			clock-frequency = < 0x186a0 >; /* in zephyr/dts/arm/nxp/nxp_mcxa344.dtsi:398 */
			#address-cells = < 0x1 >;      /* in zephyr/dts/arm/nxp/nxp_mcxa344.dtsi:399 */
			#size-cells = < 0x0 >;         /* in zephyr/dts/arm/nxp/nxp_mcxa344.dtsi:400 */
			reg = < 0x4009a000 0x1000 >;   /* in zephyr/dts/arm/nxp/nxp_mcxa344.dtsi:401 */
			interrupts = < 0x1a 0x0 >;     /* in zephyr/dts/arm/nxp/nxp_mcxa344.dtsi:402 */
			clocks = < &syscon 0x1400 >;   /* in zephyr/dts/arm/nxp/nxp_mcxa344.dtsi:403 */
			status = "disabled";           /* in zephyr/dts/arm/nxp/nxp_mcxa344.dtsi:404 */
		};

		/* node '/soc/i2c@4009b000' defined in zephyr/dts/arm/nxp/nxp_mcxa344.dtsi:407 */
		lpi2c1: i2c@4009b000 {
			compatible = "nxp,lpi2c";      /* in zephyr/dts/arm/nxp/nxp_mcxa344.dtsi:408 */
			clock-frequency = < 0x186a0 >; /* in zephyr/dts/arm/nxp/nxp_mcxa344.dtsi:409 */
			#address-cells = < 0x1 >;      /* in zephyr/dts/arm/nxp/nxp_mcxa344.dtsi:410 */
			#size-cells = < 0x0 >;         /* in zephyr/dts/arm/nxp/nxp_mcxa344.dtsi:411 */
			reg = < 0x4009b000 0x1000 >;   /* in zephyr/dts/arm/nxp/nxp_mcxa344.dtsi:412 */
			interrupts = < 0x1b 0x0 >;     /* in zephyr/dts/arm/nxp/nxp_mcxa344.dtsi:413 */
			clocks = < &syscon 0x1401 >;   /* in zephyr/dts/arm/nxp/nxp_mcxa344.dtsi:414 */
			status = "disabled";           /* in zephyr/dts/arm/nxp/nxp_mcxa344.dtsi:415 */
		};

		/* node '/soc/spi@4009c000' defined in zephyr/dts/arm/nxp/nxp_mcxa344.dtsi:418 */
		lpspi0: spi@4009c000 {
			compatible = "nxp,lpspi";    /* in zephyr/dts/arm/nxp/nxp_mcxa344.dtsi:419 */
			reg = < 0x4009c000 0x1000 >; /* in zephyr/dts/arm/nxp/nxp_mcxa344.dtsi:420 */
			interrupts = < 0x1c 0x0 >;   /* in zephyr/dts/arm/nxp/nxp_mcxa344.dtsi:421 */
			clocks = < &syscon 0x1700 >; /* in zephyr/dts/arm/nxp/nxp_mcxa344.dtsi:422 */
			tx-fifo-size = < 0x4 >;      /* in zephyr/dts/arm/nxp/nxp_mcxa344.dtsi:423 */
			rx-fifo-size = < 0x4 >;      /* in zephyr/dts/arm/nxp/nxp_mcxa344.dtsi:424 */
			#address-cells = < 0x1 >;    /* in zephyr/dts/arm/nxp/nxp_mcxa344.dtsi:425 */
			#size-cells = < 0x0 >;       /* in zephyr/dts/arm/nxp/nxp_mcxa344.dtsi:426 */
			status = "disabled";         /* in zephyr/dts/arm/nxp/nxp_mcxa344.dtsi:427 */
		};

		/* node '/soc/spi@4009d000' defined in zephyr/dts/arm/nxp/nxp_mcxa344.dtsi:430 */
		lpspi1: spi@4009d000 {
			compatible = "nxp,lpspi";    /* in zephyr/dts/arm/nxp/nxp_mcxa344.dtsi:431 */
			reg = < 0x4009d000 0x1000 >; /* in zephyr/dts/arm/nxp/nxp_mcxa344.dtsi:432 */
			interrupts = < 0x1d 0x0 >;   /* in zephyr/dts/arm/nxp/nxp_mcxa344.dtsi:433 */
			clocks = < &syscon 0x1701 >; /* in zephyr/dts/arm/nxp/nxp_mcxa344.dtsi:434 */
			tx-fifo-size = < 0x4 >;      /* in zephyr/dts/arm/nxp/nxp_mcxa344.dtsi:435 */
			rx-fifo-size = < 0x4 >;      /* in zephyr/dts/arm/nxp/nxp_mcxa344.dtsi:436 */
			#address-cells = < 0x1 >;    /* in zephyr/dts/arm/nxp/nxp_mcxa344.dtsi:437 */
			#size-cells = < 0x0 >;       /* in zephyr/dts/arm/nxp/nxp_mcxa344.dtsi:438 */
			status = "disabled";         /* in zephyr/dts/arm/nxp/nxp_mcxa344.dtsi:439 */
		};

		/* node '/soc/lptmr@400ab000' defined in zephyr/dts/arm/nxp/nxp_mcxa344.dtsi:442 */
		lptmr0: lptmr@400ab000 {
			compatible = "nxp,lptmr";         /* in zephyr/dts/arm/nxp/nxp_mcxa344.dtsi:443 */
			reg = < 0x400ab000 0x1000 >;      /* in zephyr/dts/arm/nxp/nxp_mcxa344.dtsi:444 */
			interrupts = < 0x37 0x0 >;        /* in zephyr/dts/arm/nxp/nxp_mcxa344.dtsi:445 */
			clock-frequency = < 0x3e80 >;     /* in zephyr/dts/arm/nxp/nxp_mcxa344.dtsi:446 */
			prescale-glitch-filter = < 0x0 >; /* in zephyr/dts/arm/nxp/nxp_mcxa344.dtsi:447 */
			clk-source = < 0x1 >;             /* in zephyr/dts/arm/nxp/nxp_mcxa344.dtsi:448 */
			resolution = < 0x20 >;            /* in zephyr/dts/arm/nxp/nxp_mcxa344.dtsi:449 */
			status = "disabled";              /* in zephyr/dts/arm/nxp/nxp_mcxa344.dtsi:450 */
		};

		/* node '/soc/timers@400ad000' defined in zephyr/dts/arm/nxp/nxp_mcxa344.dtsi:453 */
		ostimer0: timers@400ad000 {
			compatible = "nxp,os-timer"; /* in zephyr/dts/arm/nxp/nxp_mcxa344.dtsi:454 */
			reg = < 0x400ad000 0x1000 >; /* in zephyr/dts/arm/nxp/nxp_mcxa344.dtsi:455 */
			interrupts = < 0x39 0x0 >;   /* in zephyr/dts/arm/nxp/nxp_mcxa344.dtsi:456 */
			status = "disabled";         /* in zephyr/dts/arm/nxp/nxp_mcxa344.dtsi:457 */
		};

		/* node '/soc/temp0' defined in zephyr/dts/arm/nxp/nxp_mcxa344.dtsi:460 */
		temp0: temp0 {
			compatible = "nxp,lpadc-temp40"; /* in zephyr/dts/arm/nxp/nxp_mcxa344.dtsi:461 */
			status = "disabled";             /* in zephyr/dts/arm/nxp/nxp_mcxa344.dtsi:462 */
		};

		/* node '/soc/watchdog@4000c000' defined in zephyr/dts/arm/nxp/nxp_mcxa344.dtsi:465 */
		wwdt0: watchdog@4000c000 {
			compatible = "nxp,lpc-wwdt"; /* in zephyr/dts/arm/nxp/nxp_mcxa344.dtsi:466 */
			reg = < 0x4000c000 0x1000 >; /* in zephyr/dts/arm/nxp/nxp_mcxa344.dtsi:467 */
			interrupts = < 0x3c 0x0 >;   /* in zephyr/dts/arm/nxp/nxp_mcxa344.dtsi:468 */
			status = "disabled";         /* in zephyr/dts/arm/nxp/nxp_mcxa344.dtsi:469 */
			clk-divider = < 0x1 >;       /* in zephyr/dts/arm/nxp/nxp_mcxa344.dtsi:470 */
		};
	};

	/* node '/cpus' defined in zephyr/dts/arm/nxp/nxp_mcxa344.dtsi:14 */
	cpus {
		#address-cells = < 0x1 >; /* in zephyr/dts/arm/nxp/nxp_mcxa344.dtsi:15 */
		#size-cells = < 0x0 >;    /* in zephyr/dts/arm/nxp/nxp_mcxa344.dtsi:16 */

		/* node '/cpus/cpu@0' defined in zephyr/dts/arm/nxp/nxp_mcxa344.dtsi:18 */
		cpu0: cpu@0 {
			compatible = "arm,cortex-m33f";  /* in zephyr/dts/arm/nxp/nxp_mcxa344.dtsi:19 */
			reg = < 0x0 >;                   /* in zephyr/dts/arm/nxp/nxp_mcxa344.dtsi:20 */
			#address-cells = < 0x1 >;        /* in zephyr/dts/arm/nxp/nxp_mcxa344.dtsi:21 */
			#size-cells = < 0x1 >;           /* in zephyr/dts/arm/nxp/nxp_mcxa344.dtsi:22 */
			clock-frequency = < 0xaba9500 >; /* in zephyr/boards/nxp/frdm_mcxa344/frdm_mcxa344.dts:101 */
		};
	};

	/* node '/pinctrl' defined in zephyr/dts/arm/nxp/nxp_mcxa344.dtsi:27 */
	pinctrl: pinctrl {
		compatible = "nxp,port-pinctrl"; /* in zephyr/dts/arm/nxp/nxp_mcxa344.dtsi:28 */
		status = "okay";                 /* in zephyr/dts/arm/nxp/nxp_mcxa344.dtsi:29 */

		/* node '/pinctrl/pinmux_lpuart2' defined in zephyr/boards/nxp/frdm_mcxa344/frdm_mcxa344-pinctrl.dtsi:10 */
		pinmux_lpuart2: pinmux_lpuart2 {
			phandle = < 0x9 >; /* in zephyr/boards/nxp/frdm_mcxa344/frdm_mcxa344.dts:131 */

			/* node '/pinctrl/pinmux_lpuart2/group0' defined in zephyr/boards/nxp/frdm_mcxa344/frdm_mcxa344-pinctrl.dtsi:11 */
			group0 {
				pinmux = < 0x20c00300 >,
				         < 0x20800300 >; /* in zephyr/boards/nxp/frdm_mcxa344/frdm_mcxa344-pinctrl.dtsi:12 */
				drive-strength = "low";  /* in zephyr/boards/nxp/frdm_mcxa344/frdm_mcxa344-pinctrl.dtsi:14 */
				slew-rate = "fast";      /* in zephyr/boards/nxp/frdm_mcxa344/frdm_mcxa344-pinctrl.dtsi:15 */
				input-enable;            /* in zephyr/boards/nxp/frdm_mcxa344/frdm_mcxa344-pinctrl.dtsi:16 */
			};
		};
	};

	/* node '/cmc' defined in zephyr/dts/arm/nxp/nxp_mcxa344.dtsi:32 */
	cmc {
		compatible = "nxp,cmc-reset-cause"; /* in zephyr/dts/arm/nxp/nxp_mcxa344.dtsi:33 */
	};

	/* node '/leds' defined in zephyr/boards/nxp/frdm_mcxa344/frdm_mcxa344.dts:35 */
	leds {
		compatible = "gpio-leds"; /* in zephyr/boards/nxp/frdm_mcxa344/frdm_mcxa344.dts:36 */

		/* node '/leds/led_0' defined in zephyr/boards/nxp/frdm_mcxa344/frdm_mcxa344.dts:38 */
		red_led: led_0 {
			gpios = < &gpio3 0x12 0x1 >; /* in zephyr/boards/nxp/frdm_mcxa344/frdm_mcxa344.dts:39 */
			label = "Red LED";           /* in zephyr/boards/nxp/frdm_mcxa344/frdm_mcxa344.dts:40 */
		};

		/* node '/leds/led_1' defined in zephyr/boards/nxp/frdm_mcxa344/frdm_mcxa344.dts:43 */
		green_led: led_1 {
			gpios = < &gpio3 0x13 0x1 >; /* in zephyr/boards/nxp/frdm_mcxa344/frdm_mcxa344.dts:44 */
			label = "Green LED";         /* in zephyr/boards/nxp/frdm_mcxa344/frdm_mcxa344.dts:45 */
		};

		/* node '/leds/led_2' defined in zephyr/boards/nxp/frdm_mcxa344/frdm_mcxa344.dts:48 */
		blue_led: led_2 {
			gpios = < &gpio3 0x15 0x1 >; /* in zephyr/boards/nxp/frdm_mcxa344/frdm_mcxa344.dts:49 */
			label = "Blue LED";          /* in zephyr/boards/nxp/frdm_mcxa344/frdm_mcxa344.dts:50 */
		};
	};

	/* node '/gpio_keys' defined in zephyr/boards/nxp/frdm_mcxa344/frdm_mcxa344.dts:54 */
	gpio_keys {
		compatible = "gpio-keys"; /* in zephyr/boards/nxp/frdm_mcxa344/frdm_mcxa344.dts:55 */

		/* node '/gpio_keys/button_2' defined in zephyr/boards/nxp/frdm_mcxa344/frdm_mcxa344.dts:57 */
		user_button_2: button_2 {
			label = "User SW2";         /* in zephyr/boards/nxp/frdm_mcxa344/frdm_mcxa344.dts:58 */
			gpios = < &gpio1 0x7 0x1 >; /* in zephyr/boards/nxp/frdm_mcxa344/frdm_mcxa344.dts:59 */
			zephyr,code = < 0xb >;      /* in zephyr/boards/nxp/frdm_mcxa344/frdm_mcxa344.dts:60 */
		};

		/* node '/gpio_keys/button_3' defined in zephyr/boards/nxp/frdm_mcxa344/frdm_mcxa344.dts:63 */
		user_button_3: button_3 {
			label = "User SW3";         /* in zephyr/boards/nxp/frdm_mcxa344/frdm_mcxa344.dts:64 */
			gpios = < &gpio0 0x6 0x1 >; /* in zephyr/boards/nxp/frdm_mcxa344/frdm_mcxa344.dts:65 */
			zephyr,code = < 0x2 >;      /* in zephyr/boards/nxp/frdm_mcxa344/frdm_mcxa344.dts:66 */
		};
	};

	/* node '/arduino-connector' defined in zephyr/boards/nxp/frdm_mcxa344/frdm_mcxa344.dts:70 */
	arduino_header: arduino-connector {
		compatible = "arduino-header-r3";          /* in zephyr/boards/nxp/frdm_mcxa344/frdm_mcxa344.dts:71 */
		#gpio-cells = < 0x2 >;                     /* in zephyr/boards/nxp/frdm_mcxa344/frdm_mcxa344.dts:72 */
		gpio-map-mask = < 0xffffffff 0xffffffc0 >; /* in zephyr/boards/nxp/frdm_mcxa344/frdm_mcxa344.dts:73 */
		gpio-map-pass-thru = < 0x0 0x3f >;         /* in zephyr/boards/nxp/frdm_mcxa344/frdm_mcxa344.dts:74 */
		gpio-map = < 0x0 0x0 &gpio1 0xe 0x0 >,
		           < 0x1 0x0 &gpio2 0x5 0x0 >,
		           < 0x2 0x0 &gpio2 0x7 0x0 >,
		           < 0x3 0x0 &gpio3 0x1e 0x0 >,
		           < 0x4 0x0 &gpio1 0x0 0x0 >,
		           < 0x5 0x0 &gpio1 0x1 0x0 >,
		           < 0x6 0x0 &gpio2 0x3 0x0 >,
		           < 0x7 0x0 &gpio2 0x2 0x0 >,
		           < 0x8 0x0 &gpio3 0xc 0x0 >,
		           < 0x9 0x0 &gpio3 0xe 0x0 >,
		           < 0xa 0x0 &gpio1 0xf 0x0 >,
		           < 0xb 0x0 &gpio3 0x1 0x0 >,
		           < 0xc 0x0 &gpio3 0x11 0x0 >,
		           < 0xd 0x0 &gpio3 0x16 0x0 >,
		           < 0xe 0x0 &gpio4 0x3 0x0 >,
		           < 0xf 0x0 &gpio3 0xd 0x0 >,
		           < 0x10 0x0 &gpio3 0xb 0x0 >,
		           < 0x11 0x0 &gpio3 0x8 0x0 >,
		           < 0x12 0x0 &gpio3 0x9 0x0 >,
		           < 0x13 0x0 &gpio3 0xa 0x0 >,
		           < 0x14 0x0 &gpio1 0x8 0x0 >,
		           < 0x15 0x0 &gpio1 0x9 0x0 >;    /* in zephyr/boards/nxp/frdm_mcxa344/frdm_mcxa344.dts:75 */
	};
};
